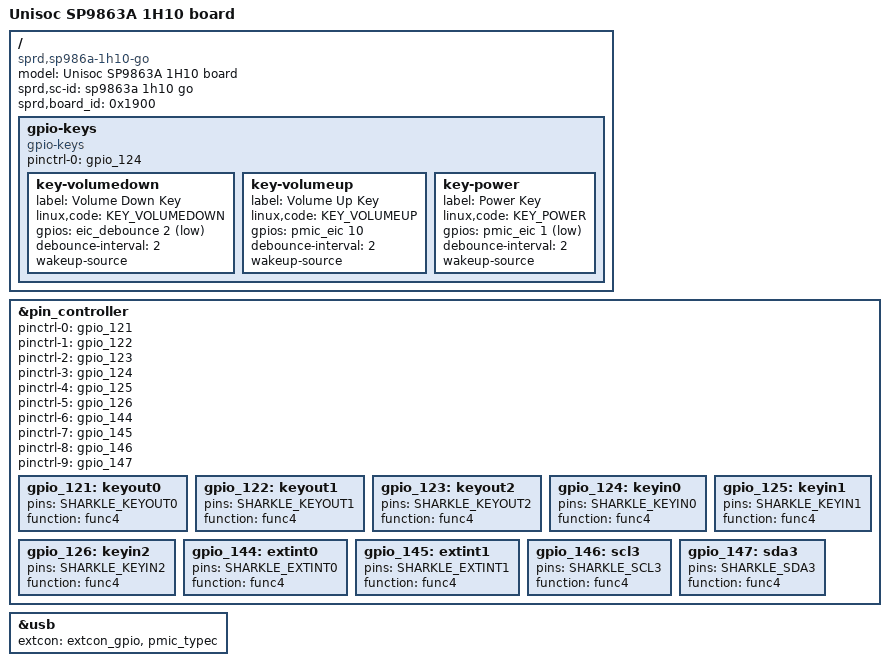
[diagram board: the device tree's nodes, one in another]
// SPDX-License-Identifier: GPL-2.0-only
/*
 * UNISOC SP9863 board common DTS file
 *
 * Copyright (C) 2021, Unisoc Inc.
 */

/dts-v1/;
/plugin/;

#include "lcd/lcd_dummy_mipi.dtsi"
#include "reserved-memory/sp9863a-1h10-overlay.dtsi"
#include <dt-bindings/input/input.h>
#include <dt-bindings/gpio/gpio.h>
#include "touchscreen/sp9863a-i2c3-gpio144-145-tp.dtsi"

/ {
	model = "Unisoc SP9863A 1H10 board";

	compatible = "sprd,sp986a-1h10-go";

	sprd,sc-id = "sp9863a 1h10 go";

	sprd,board_id = <0x1900>; //XX00:base board,XX00~XXFF:customize board

	fragment {
		target-path = "/";
		__overlay__ {
			gpio-keys {
				compatible = "gpio-keys";
				pinctrl-names = "gpio_124";
				pinctrl-0 = <&gpio_124>;

				key-volumedown {
					label = "Volume Down Key";
					linux,code = <KEY_VOLUMEDOWN>;
					gpios = <&eic_debounce 2 GPIO_ACTIVE_LOW>;
					debounce-interval = <2>;
					wakeup-source;
				};
				key-volumeup {
					label = "Volume Up Key";
					linux,code = <KEY_VOLUMEUP>;
					gpios = <&pmic_eic 10 GPIO_ACTIVE_HIGH>;
					debounce-interval = <2>;
					wakeup-source;
				};
				key-power {
					label = "Power Key";
					linux,code =<KEY_POWER>;
					gpios = <&pmic_eic 1 GPIO_ACTIVE_LOW>;
					debounce-interval = <2>;
					wakeup-source;
				};
			};
		};
	};
};

&pin_controller {
	pinctrl-names =
	/* keyout0 ~ keyout2 */
	"gpio_121", "gpio_122", "gpio_123",
	/* keyin0 ~ keyin2 */
	"gpio_124", "gpio_125", "gpio_126",
	/* extint0, extint1, scl3, sda3 */
	"gpio_144", "gpio_145", "gpio_146", "gpio_147",
	/* Note:If create a new board,need to add the shutdown node */
	"shutdown";
	pinctrl-0 = <&gpio_121>;
	pinctrl-1 = <&gpio_122>;
	pinctrl-2 = <&gpio_123>;
	pinctrl-3 = <&gpio_124>;
	pinctrl-4 = <&gpio_125>;
	pinctrl-5 = <&gpio_126>;
	pinctrl-6 = <&gpio_144>;
	pinctrl-7 = <&gpio_145>;
	pinctrl-8 = <&gpio_146>;
	pinctrl-9 = <&gpio_147>;

	gpio_121: keyout0 {
		pins = "SHARKLE_KEYOUT0";
		function = "func4";
	};

	gpio_122: keyout1 {
		pins = "SHARKLE_KEYOUT1";
		function = "func4";
	};

	gpio_123: keyout2 {
		pins = "SHARKLE_KEYOUT2";
		function = "func4";
	};

	gpio_124: keyin0 {
		pins = "SHARKLE_KEYIN0";
		function = "func4";
	};

	gpio_125: keyin1 {
		pins = "SHARKLE_KEYIN1";
		function = "func4";
	};

	gpio_126: keyin2 {
		pins = "SHARKLE_KEYIN2";
		function = "func4";
	};

	gpio_144: extint0 {
		pins = "SHARKLE_EXTINT0";
		function = "func4";
	};

	gpio_145: extint1 {
		pins = "SHARKLE_EXTINT1";
		function = "func4";
	};

	gpio_146: scl3 {
		pins = "SHARKLE_SCL3";
		function = "func4";
	};

	gpio_147: sda3 {
		pins = "SHARKLE_SDA3";
		function = "func4";
	};
};

&usb{
	extcon = <&extcon_gpio>, <&pmic_typec>;
	status = "okay";
	/*vbus-supply = <&vddvbus>;*/
};
